VERSION "1"

NS_ :

BS_:

BU_: Dash DataLogger Ethanol Controller

BO_ 256 Dash_Engine: 4 Dash
 SG_ Rpm : 0|16@1+ (1,0) [0|8000] "rpm" DataLogger
 SG_ Speed : 16|16@1+ (0.01,0) [0|655.35] "km/h" DataLogger

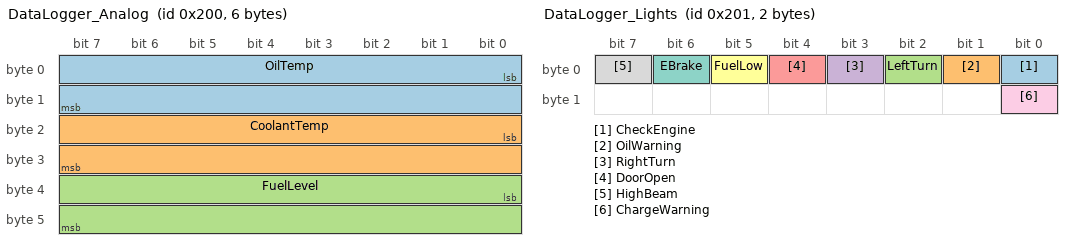
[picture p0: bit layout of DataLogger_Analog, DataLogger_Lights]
BO_ 512 DataLogger_Analog: 6 DataLogger
 SG_ OilTemp : 0|16@1- (0.1,0) [-3276.8|3276.7] "degC" Dash
 SG_ CoolantTemp : 16|16@1- (0.1,0) [-3276.8|3276.7] "degC" Dash
 SG_ FuelLevel : 32|16@1+ (0.1,0) [0|6553.5] "%" Dash

BO_ 513 DataLogger_Lights: 2 DataLogger
 SG_ CheckEngine : 0|1@1+ (1,0) [0|1] "" Dash
 SG_ OilWarning : 1|1@1+ (1,0) [0|1] "" Dash
 SG_ LeftTurn : 2|1@1+ (1,0) [0|1] "" Dash
 SG_ RightTurn : 3|1@1+ (1,0) [0|1] "" Dash
 SG_ DoorOpen : 4|1@1+ (1,0) [0|1] "" Dash
 SG_ FuelLow : 5|1@1+ (1,0) [0|1] "" Dash
 SG_ EBrake : 6|1@1+ (1,0) [0|1] "" Dash
 SG_ HighBeam : 7|1@1+ (1,0) [0|1] "" Dash
 SG_ ChargeWarning : 8|1@1+ (1,0) [0|1] "" Dash

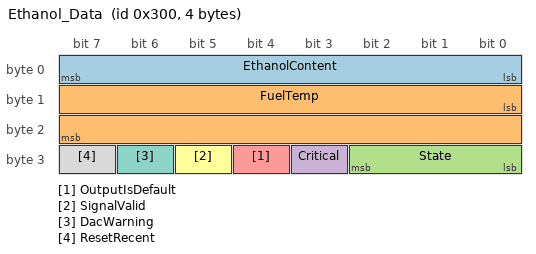
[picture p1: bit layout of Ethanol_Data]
BO_ 768 Ethanol_Data: 4 Ethanol
 SG_ EthanolContent : 0|8@1+ (1,0) [0|100] "%" Dash,DataLogger
 SG_ FuelTemp : 8|16@1- (0.1,0) [-3276.8|3276.7] "degC" Dash,DataLogger
 SG_ State : 24|3@1+ (1,0) [0|4] "" Dash,DataLogger
 SG_ Critical : 27|1@1+ (1,0) [0|1] "" Dash,DataLogger
 SG_ OutputIsDefault : 28|1@1+ (1,0) [0|1] "" Dash,DataLogger
 SG_ SignalValid : 29|1@1+ (1,0) [0|1] "" Dash,DataLogger
 SG_ DacWarning : 30|1@1+ (1,0) [0|1] "" Dash,DataLogger
 SG_ ResetRecent : 31|1@1+ (1,0) [0|1] "" Dash,DataLogger

BO_ 1793 Heartbeat_Dash: 2 Dash
 SG_ Status : 0|8@1+ (1,0) [0|255] "" DataLogger,Ethanol
 SG_ Counter : 8|8@1+ (1,0) [0|255] "" DataLogger,Ethanol

BO_ 1794 Heartbeat_DataLogger: 2 DataLogger
 SG_ Status : 0|8@1+ (1,0) [0|255] "" Dash,Ethanol
 SG_ Counter : 8|8@1+ (1,0) [0|255] "" Dash,Ethanol

BO_ 1795 Heartbeat_Ethanol: 2 Ethanol
 SG_ Status : 0|8@1+ (1,0) [0|255] "" Dash,DataLogger
 SG_ Counter : 8|8@1+ (1,0) [0|255] "" Dash,DataLogger

BO_ 515 DataLogger_OilPressure: 2 DataLogger
 SG_ OilPressure : 0|16@1+ (0.01,0) [0|655.35] "bar" Dash

BO_ 514 DataLogger_Status: 1 DataLogger
 SG_ LogMode : 0|2@1+ (1,0) [0|1] "" Dash,Controller
 SG_ CardState : 2|2@1+ (1,0) [0|3] "" Dash,Controller

BO_ 1024 Logger_Control: 1 Controller
 SG_ LogButton : 0|1@1+ (1,0) [0|1] "" DataLogger

BA_DEF_ BO_ "GenMsgCycleTime" INT 0 65535;
BA_DEF_DEF_ "GenMsgCycleTime" 0;
BA_ "GenMsgCycleTime" BO_ 256 20;
BA_ "GenMsgCycleTime" BO_ 512 100;
BA_ "GenMsgCycleTime" BO_ 515 20;
BA_ "GenMsgCycleTime" BO_ 513 100;
BA_ "GenMsgCycleTime" BO_ 514 200;
BA_ "GenMsgCycleTime" BO_ 768 100;
BA_ "GenMsgCycleTime" BO_ 1793 1000;
BA_ "GenMsgCycleTime" BO_ 1794 1000;
BA_ "GenMsgCycleTime" BO_ 1795 1000;
BA_ "GenMsgCycleTime" BO_ 1024 100;

CM_ BO_ 515 "Oil pressure alone, at 50 Hz (the logging-rate spec, docs/logging-rates.md), so the slow temperatures and fuel level do not ride at the fast rate and the oil-pressure alarm does not depend on them. Split from DataLogger_Analog (TCAN-28): older logs have the old 8-byte 0x200 layout with oil pressure first.";
CM_ BO_ 512 "Oil temperature, coolant temperature and fuel level, at 10 Hz. Oil pressure moved to DataLogger_OilPressure (0x203) in TCAN-28; this message was 8 bytes with oil pressure first.";
CM_ SG_ 768 FuelTemp "-3276.8 (raw 0x8000) means the fuel temperature is invalid.";
CM_ SG_ 768 State "Ethanol output state. 0 Boot (output is the E85 default), 1 Qualifying, 2 Ok, 3 Holding (sensor lost, last qualified value held), 4 Critical.";
CM_ SG_ 768 Critical "1 = extreme fault: show the big error. Latched until power cycle, except Never Qualified which clears once the sensor qualifies.";
CM_ SG_ 768 OutputIsDefault "1 = the value sent to the ECU is the E85 default, not a measurement.";
CM_ SG_ 768 SignalValid "1 = the sensor signal is currently valid.";
CM_ SG_ 768 DacWarning "1 = the DAC readback differs from the commanded output by a small amount (warning only).";
CM_ SG_ 768 ResetRecent "1 = the node restarted from a watchdog reset since power-up.";
CM_ SG_ 1795 Status "Ethanol Node active fault code, highest priority first: 4, 3, 6, 5, 2, 1. See value table.";

CM_ SG_ 514 LogMode "DataLogger logging mode. 0 Daily (low rate, always on), 1 HighRes (every frame, started by the Logger_Control button and ended by it or by a time limit).";
CM_ SG_ 514 CardState "SD card state. 0 Starting, 1 NoCard (not inserted, not seated or not answering), 2 Error (file system error), 3 Logging.";
CM_ SG_ 1024 LogButton "1 = the logging button is pressed (a level, sent about every 100 ms and on change). The DataLogger toggles high-res logging on each press (rising edge). Source node TBD: a dash button, a CAN keypad or d-pad.";

VAL_ 514 LogMode 0 "Daily" 1 "HighRes";
VAL_ 514 CardState 0 "Starting" 1 "NoCard" 2 "Error" 3 "Logging";
VAL_ 768 State 0 "Boot" 1 "Qualifying" 2 "Ok" 3 "Holding" 4 "Critical";
VAL_ 1795 Status 0 "None" 1 "SensorLost" 2 "NeverQualified" 3 "DacMismatch" 4 "DacOvervoltage" 5 "WatchdogReset" 6 "DacI2cFailure";
